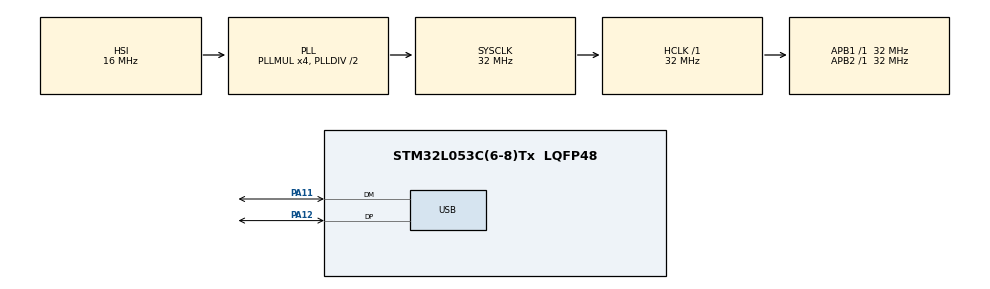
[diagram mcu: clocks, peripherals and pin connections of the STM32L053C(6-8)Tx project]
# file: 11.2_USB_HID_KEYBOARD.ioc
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Mcu.Family=STM32L0
Mcu.Name=STM32L053C(6-8)Tx
Mcu.Package=LQFP48
NVIC.USB_IRQn=true\:0\:0\:false\:false\:true\:false\:true\:true
PA11.Mode=Device
PA11.Signal=USB_DM
PA12.Mode=Device
PA12.Signal=USB_DP
PA13.Mode=Serial_Wire
PA13.Signal=SYS_SWDIO
PA14.Mode=Serial_Wire
PA14.Signal=SYS_SWCLK
ProjectManager.HeapSize=0x200
ProjectManager.StackSize=0x400
ProjectManager.TargetToolchain=STM32CubeIDE
RCC.AHBFreq_Value=32000000
RCC.APB1Freq_Value=32000000
RCC.APB1TimFreq_Value=32000000
RCC.APB2Freq_Value=32000000
RCC.APB2TimFreq_Value=32000000
RCC.HCLKFreq_Value=32000000
RCC.HSE_VALUE=8000000
RCC.HSI16_VALUE=16000000
RCC.HSI48MClockSelection=RCC_USBCLKSOURCE_HSI48
RCC.HSI48_VALUE=48000000
RCC.HSI_VALUE=16000000
RCC.LSE_VALUE=32768
RCC.MSI_VALUE=2097000
RCC.PLLMUL=RCC_PLLMUL_4
RCC.RTCClockSelectionVirtual=RCC_RTCCLKSOURCE_LSE
RCC.SYSCLKFreq_VALUE=32000000
RCC.SYSCLKSource=RCC_SYSCLKSOURCE_PLLCLK
RCC.VCOOutputFreq_Value=64000000
USB_DEVICE.CLASS_NAME_FS=HID
USB_DEVICE.VirtualMode=Hid
USB_DEVICE.VirtualModeFS=Hid_FS
VP_USB_DEVICE_VS_USB_DEVICE_HID_FS.Mode=HID_FS
board=STM32L0538-DISCO

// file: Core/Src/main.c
/* USER CODE BEGIN Header */
/**
  ******************************************************************************
  * @file           : main.c
  * @brief          : Main program body
  ******************************************************************************
  * @attention
  *
  * Copyright (c) 2024 STMicroelectronics.
  * All rights reserved.
  *
  * This software is licensed under terms that can be found in the LICENSE file
  * in the root directory of this software component.
  * If no LICENSE file comes with this software, it is provided AS-IS.
  *
  ******************************************************************************
  */
/* USER CODE END Header */
#include "main.h"
#include "usb_device.h"

/* USER CODE BEGIN Includes */
#include "usbd_hid.h"
#include "stdio.h"
/* USER CODE END Includes */

/* USER CODE BEGIN PV */
extern USBD_HID_HandleTypeDef hUsbDeviceFS;

typedef struct {
	uint8_t MODIFIER;
	uint8_t RESERVED;
	uint8_t KEYCODE1;
	uint8_t KEYCODE2;
	uint8_t KEYCODE3;
	uint8_t KEYCODE4;
	uint8_t KEYCODE5;
	uint8_t KEYCODE6;

}keyboardReportDes;

keyboardReportDes HIDkeyBoard = {0,0,0,0,0,0,0,0};

char msg_buff[100];
/* USER CODE END PV */

void SystemClock_Config(void);
static void MX_GPIO_Init(void);

/* USER CODE BEGIN 0 */
//void KeyBoardPrint(char *data, uint16_t length) {
//
//	for (uint16_t count = 0; count < length; count++)
//	{
//		if (data[count] >= 0x41 && data[count] <= 0x5A)
//		{
//			HIDkeyBoard.MODIFIER = 0x02;  // Print char in Capital
//			HIDkeyBoard.KEYCODE1 = data[count] - 0x3D;
//			USBD_HID_SendReport(&hUsbDeviceFS, &HIDkeyBoard, sizeof(HIDkeyBoard));
//
//			HAL_Delay(15);
//			HIDkeyBoard.MODIFIER = 0x00;
//			HIDkeyBoard.KEYCODE1 = 0x00;
//			USBD_HID_SendReport(&hUsbDeviceFS, &HIDkeyBoard, sizeof(HIDkeyBoard));
//
//		}
//		else if (data[count] >= 0x61 && data[count] <= 0x7A)
//		{
//			HIDkeyBoard.KEYCODE1 = data[count] - 0x5D;
//			USBD_HID_SendReport(&hUsbDeviceFS, &HIDkeyBoard, sizeof(HIDkeyBoard));
//
//			HAL_Delay(15);
//			HIDkeyBoard.KEYCODE1 = 0x00;
//			USBD_HID_SendReport(&hUsbDeviceFS, &HIDkeyBoard, sizeof(HIDkeyBoard));
//
//		}
//
//		else if (data[count] == 0x20)
//		{
//			HIDkeyBoard.KEYCODE1 = 0x2C;
//			USBD_HID_SendReport(&hUsbDeviceFS, &HIDkeyBoard, sizeof(HIDkeyBoard));
//
//			HAL_Delay(15);
//			HIDkeyBoard.KEYCODE1 = 0x00;
//			USBD_HID_SendReport(&hUsbDeviceFS, &HIDkeyBoard, sizeof(HIDkeyBoard));
//
//		}
//
//		else if (data[count] == 0x0A)
//		{
//			HIDkeyBoard.KEYCODE1 = 0x28;
//			USBD_HID_SendReport(&hUsbDeviceFS, &HIDkeyBoard, sizeof(HIDkeyBoard));
//
//			HAL_Delay(15);
//			HIDkeyBoard.KEYCODE1 = 0x00;
//			USBD_HID_SendReport(&hUsbDeviceFS, &HIDkeyBoard, sizeof(HIDkeyBoard));
//
//		}
//		HAL_Delay(25);
//	}
//}
void KeyBoardPrint(char *data, uint16_t length) {
    for (uint16_t count = 0; count < length; count++) {
        if (data[count] >= 0x41 && data[count] <= 0x5A) { // Uppercase A-Z
            HIDkeyBoard.MODIFIER = 0x06;  // Left Shift
            HIDkeyBoard.KEYCODE1 = data[count] - 0x3D;
        } else if (data[count] >= 0x61 && data[count] <= 0x7A) { // Lowercase a-z
            HIDkeyBoard.KEYCODE1 = data[count] - 0x5D;
        } else if (data[count] == 0x20) { // Space
            HIDkeyBoard.KEYCODE1 = 0x2C;
        } else if (data[count] == 0x0A) { // New line
            HIDkeyBoard.KEYCODE1 = 0x28;
        } else {
            HIDkeyBoard.KEYCODE1 = 0x00;
        }

        USBD_HID_SendReport(&hUsbDeviceFS, &HIDkeyBoard, sizeof(HIDkeyBoard));
        HAL_Delay(15);

        HIDkeyBoard.MODIFIER = 0x00;
        HIDkeyBoard.KEYCODE1 = 0x00;
        USBD_HID_SendReport(&hUsbDeviceFS, &HIDkeyBoard, sizeof(HIDkeyBoard));
        HAL_Delay(25);
    }
}
/* USER CODE END 0 */

int main(void)
{

  /* MCU Configuration--------------------------------------------------------*/

  /* Reset of all peripherals, Initializes the Flash interface and the Systick. */
  HAL_Init();

  /* Configure the system clock */
  SystemClock_Config();

  /* Initialize all configured peripherals */
  MX_GPIO_Init();
  MX_USB_DEVICE_Init();
  /* USER CODE BEGIN 2 */
  sprintf(msg_buff, "hello, i am dishantpari\r\n ");
  /* USER CODE END 2 */

  /* Infinite loop */
  while (1)
  {

    /* USER CODE BEGIN 3 */
	/*
	 * This a basic ABC printing in every 1 sec
	HIDkeyBoard.MODIFIER = 0x02;  // Print char in Capital
	HIDkeyBoard.KEYCODE1 = 0x04;  // Print 'A'
	HIDkeyBoard.KEYCODE2 = 0x05;  // Print 'B'
	HIDkeyBoard.KEYCODE3 = 0x06;  // Print 'C'
	USBD_HID_SendReport(&hUsbDeviceFS, &HIDkeyBoard, sizeof(HIDkeyBoard));
	HAL_Delay(50);

	HIDkeyBoard.MODIFIER = 0x00;  // Clear input
	HIDkeyBoard.KEYCODE1 = 0x00;  // Clear input
	HIDkeyBoard.KEYCODE2 = 0x00;  // Clear input
	HIDkeyBoard.KEYCODE3 = 0x00;  // Clear input
	USBD_HID_SendReport(&hUsbDeviceFS, &HIDkeyBoard, sizeof(HIDkeyBoard));
	HAL_Delay(1000);
	*/

	  /** Now we set our name and print it every 2 sec**/
	  /*
		 HIDkeyBoard.MODIFIER = 0x02;  // Print char in Capital
	HIDkeyBoard.KEYCODE1 = 0x07;  // Print 'D'
	HIDkeyBoard.KEYCODE2 = 0x0C;  // Print 'I'
	HIDkeyBoard.KEYCODE3 = 0x16;  // Print 'S'
	HIDkeyBoard.KEYCODE4 = 0x0B;  // Print 'H'
	HIDkeyBoard.KEYCODE5 = 0x04;  // Print 'A'
	HIDkeyBoard.KEYCODE6 = 0x11;  // Print 'N'
	USBD_HID_SendReport(&hUsbDeviceFS, &HIDkeyBoard, sizeof(HIDkeyBoard));
	HAL_Delay(100);

//	HIDkeyBoard.MODIFIER = 0x00;  // Clear input
	HIDkeyBoard.KEYCODE1 = 0x00;  // Clear input
	HIDkeyBoard.KEYCODE2 = 0x00;  // Clear input
	HIDkeyBoard.KEYCODE3 = 0x00;  // Clear input
	HIDkeyBoard.KEYCODE4 = 0x00;  // Clear input
	HIDkeyBoard.KEYCODE5 = 0x00;  // Clear input
	HIDkeyBoard.KEYCODE6 = 0x00;  // Clear input
	USBD_HID_SendReport(&hUsbDeviceFS, &HIDkeyBoard, sizeof(HIDkeyBoard));
	HAL_Delay(100);

//	HIDkeyBoard.MODIFIER = 0x02;  // Print char in Capital
	HIDkeyBoard.KEYCODE1 = 0x17;  // Print 'T'
	HIDkeyBoard.KEYCODE2 = 0x13;  // Print 'P'
	HIDkeyBoard.KEYCODE3 = 0x04;  // Print 'A'
	HIDkeyBoard.KEYCODE4 = 0x15;  // Print 'R'
	HIDkeyBoard.KEYCODE5 = 0x0C;  // Print 'I'
	HIDkeyBoard.KEYCODE6 = 0x58;  // 'ENTER'
	USBD_HID_SendReport(&hUsbDeviceFS, &HIDkeyBoard, sizeof(HIDkeyBoard));
	HAL_Delay(100);

	HIDkeyBoard.MODIFIER = 0x00;  // Clear input
	HIDkeyBoard.KEYCODE1 = 0x00;  // Clear input
	HIDkeyBoard.KEYCODE2 = 0x00;  // Clear input
	HIDkeyBoard.KEYCODE3 = 0x00;  // Clear input
	HIDkeyBoard.KEYCODE4 = 0x00;  // Clear input
	HIDkeyBoard.KEYCODE5 = 0x00;  // Clear input
	HIDkeyBoard.KEYCODE6 = 0x00;  // Clear input
	USBD_HID_SendReport(&hUsbDeviceFS, &HIDkeyBoard, sizeof(HIDkeyBoard));

	HAL_Delay(1000);
	*/

	KeyBoardPrint(msg_buff, strlen(msg_buff));
	HAL_Delay(100);
  }
  /* USER CODE END 3 */
}

void SystemClock_Config(void)
{
  RCC_OscInitTypeDef RCC_OscInitStruct = {0};
  RCC_ClkInitTypeDef RCC_ClkInitStruct = {0};
  RCC_PeriphCLKInitTypeDef PeriphClkInit = {0};

  /** Configure the main internal regulator output voltage
  */
  __HAL_PWR_VOLTAGESCALING_CONFIG(PWR_REGULATOR_VOLTAGE_SCALE1);

  /** Initializes the RCC Oscillators according to the specified parameters
  * in the RCC_OscInitTypeDef structure.
  */
  RCC_OscInitStruct.OscillatorType = RCC_OSCILLATORTYPE_HSI|RCC_OSCILLATORTYPE_HSI48;
  RCC_OscInitStruct.HSIState = RCC_HSI_ON;
  RCC_OscInitStruct.HSICalibrationValue = RCC_HSICALIBRATION_DEFAULT;
  RCC_OscInitStruct.HSI48State = RCC_HSI48_ON;
  RCC_OscInitStruct.PLL.PLLState = RCC_PLL_ON;
  RCC_OscInitStruct.PLL.PLLSource = RCC_PLLSOURCE_HSI;
  RCC_OscInitStruct.PLL.PLLMUL = RCC_PLLMUL_4;
  RCC_OscInitStruct.PLL.PLLDIV = RCC_PLLDIV_2;
  if (HAL_RCC_OscConfig(&RCC_OscInitStruct) != HAL_OK)
  {
    Error_Handler();
  }

  /** Initializes the CPU, AHB and APB buses clocks
  */
  RCC_ClkInitStruct.ClockType = RCC_CLOCKTYPE_HCLK|RCC_CLOCKTYPE_SYSCLK
                              |RCC_CLOCKTYPE_PCLK1|RCC_CLOCKTYPE_PCLK2;
  RCC_ClkInitStruct.SYSCLKSource = RCC_SYSCLKSOURCE_PLLCLK;
  RCC_ClkInitStruct.AHBCLKDivider = RCC_SYSCLK_DIV1;
  RCC_ClkInitStruct.APB1CLKDivider = RCC_HCLK_DIV1;
  RCC_ClkInitStruct.APB2CLKDivider = RCC_HCLK_DIV1;

  if (HAL_RCC_ClockConfig(&RCC_ClkInitStruct, FLASH_LATENCY_1) != HAL_OK)
  {
    Error_Handler();
  }
  PeriphClkInit.PeriphClockSelection = RCC_PERIPHCLK_USB;
  PeriphClkInit.UsbClockSelection = RCC_USBCLKSOURCE_HSI48;
  if (HAL_RCCEx_PeriphCLKConfig(&PeriphClkInit) != HAL_OK)
  {
    Error_Handler();
  }
}

static void MX_GPIO_Init(void)
{

  /* GPIO Ports Clock Enable */
  __HAL_RCC_GPIOA_CLK_ENABLE();

}

void Error_Handler(void)
{
  __disable_irq();
  while (1)
  {
  }
}
